# RL6678_IP_SVD register map
Vendor: Realtek
Registers are 32-bit, read-write, reset 0x0 unless marked. A register's access mark holds for its fields unless they carry their own. Offsets are from the block's base; [hi:lo] are bit positions; {n}, {i} and the like mark numbered series.

## PMC_REG
Base 0x42008300
0x00 REG_WAK_STATUS0 ro
  [31:0] wak_sta_31_0 — wak evt status. It can't be cleare here, clear at IP side . Bit0: WIFI_FISR_FESR_IRQ_LP Bit1: WIFI_FTSR_MAILBOX_IRQ_LP Bit2: AON Timer Bit3: NP_WAKE_IRQ_LP Bit4: AP_WAKE_IRQ_LP Bit5: WDG0_IRQ_LP Bit6: Timer0 Bit7: Timer1 Bit8: Timer2 Bit9: Timer3 Bit10: Timer4 Bit11: Timer5 Bit12: Timer6 Bit13: Timer7 Bit14: UART_LOG Bit15: GPIOA Bit16: GPIOB Bit17: GPIOC Bit18: RTC Bit19: CTOUCH Bit20: ADC Bit21: ADC_COMP Bit22: BOR Bit23: PWR_DOWN Bit24: VAD Bit25: IPC_NP Bit26: IPC_AP Bit27: USB_OTG Bit28: SPI0 Bit29: SPI1 Bit30: UART0 Bit31: UART1
0x04 REG_WAK_STATUS1 ro
  [31:0] wak_sta_63_32 — wak evt status. It can't be cleare here, clear at IP side . Bit0: UART2 Bit1: WDG1 Bit2: WDG2 Bit3: WDG3 Bit4: WDG4 Bit5: AON_GPIO_WAKE Bit6: BT_WAKE_HOST Bit7: nFIQOUT0_OR_nIRQOUT0 Bit8: nFIQOUT1_OR_nIRQOUT1 Bit9~31: Reserved
0x08 REG_WAK_MASK0_LP
  [31:0] wak_lp_imr_31_0 — 1:mask enable for wake KM0, this used to wak pmc
0x0C REG_WAK_MASK1_LP
  [31:0] wak_lp_imr_63_32 — 1:mask enable for wake KM0
0x10 REG_WAK_MASK0_NP
  [31:0] wak_np_imr_31_0 — 1:mask enable for wake NP
0x14 REG_WAK_MASK1_NP
  [31:0] wak_np_imr_63_32 — 1:mask enable for wake NP
0x18 REG_WAK_MASK0_AP
  [31:0] wak_ap_imr_31_0 — 1:mask enable for wake AP
0x1C REG_WAK_MASK1_AP
  [31:0] wak_ap_imr_63_32 — 1:mask enable for wake AP
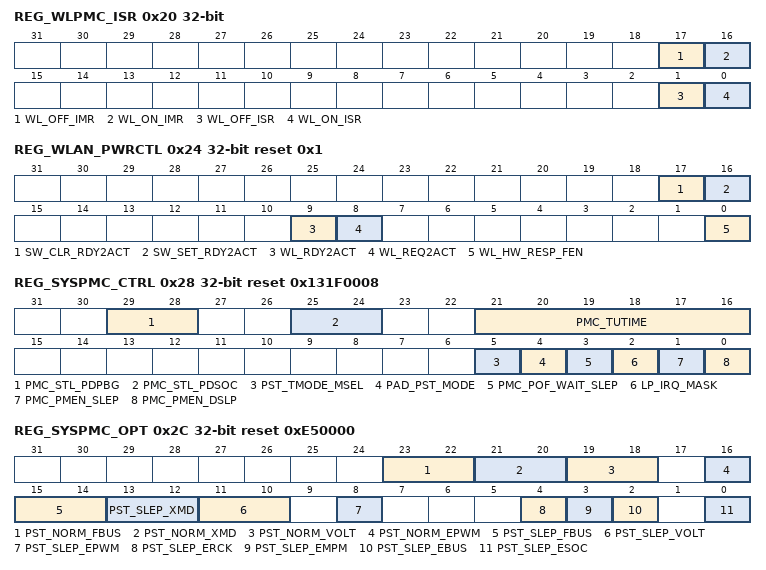
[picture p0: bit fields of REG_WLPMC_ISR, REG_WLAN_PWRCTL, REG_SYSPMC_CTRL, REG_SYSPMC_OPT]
0x20 REG_WLPMC_ISR access per field
  [17] WL_OFF_IMR rw, [16] WL_ON_IMR rw, [1] WL_OFF_ISR ro, [0] WL_ON_ISR ro
0x24 REG_WLAN_PWRCTL access per field reset 0x1
  [17] SW_CLR_RDY2ACT rw — System infrom WLAN ready to active
  [16] SW_SET_RDY2ACT rw
  [9] WL_RDY2ACT ro — System infrom WLAN ready to active
  [8] WL_REQ2ACT ro
  [0] WL_HW_RESP_FEN rw — 1: enable HW auto response
0x28 REG_SYSPMC_CTRL reset 0x131F0008
  [29:28] PMC_STL_PDPBG — timer wait for PLL bandgag power stable . Spec is 160us 00:8us * 2^4 01:8us * 2^5 10:8us * 2^6 11:8us * 2^7
  [25:24] PMC_STL_PDSOC — timer wait for core power power-cut power stable . 00:8us * 2^5 01:8us * 2^6 10:8us * 2^7 11:8us * 2^8
  [21:16] PMC_TUTIME — PMC timeunit setting, in cycles of osc4M e.g, default 0x1F, timeunit = 8us
  [5] PST_TMODE_MSEL — Set ls plfm msel option . 0: when test mode , msel will set to 0 for SIC 1: when test mode , pmc will not set msel , remain as km0 master.
  [4] PAD_PST_MODE — Pad pu/pd param selection 1: HW select pu/pd slp param for PAD 0: HW select pu/pd active param for PAD HW will auto-set this bit when enter or exit DSLP , SW can set for debug also .
  [3] PMC_POF_WAIT_SLEP — 1.when SW set pmen_slep or pmen_dslp , hw pmc will wait km0 enter sleep mode , then begin to pof seq 0.Not wait km0 sleep
  [2] LP_IRQ_MASK — 1.mask all LP interrupt 0:release all LP interrupt
  [1] PMC_PMEN_SLEP — 1: Request PMC to enter sleep state, auto clear to 0 after PMC finishes
  [0] PMC_PMEN_DSLP — 1: Request PMC to enter deep-sleep state, auto clear to 0 after PMC finishes
0x2C REG_SYSPMC_OPT reset 0xE50000
  [23:22] PST_NORM_FBUS — Normal setting for ls bus frequency selection 2'b00/01: ANA4M 2'b10: XTAL 2'b11: XTAL/2
  [21:20] PST_NORM_XMD — Normal setting for XTAL mode selection 00: XTAL will be off when PMC enter into sleep mode 01: XTAL will be in LPS when PMC enter into sleep mode 10/11: XTAL will be in Normal when PMC enter into sleep mode
  [19:18] PST_NORM_VOLT — Normal setting for SWR volt selection 00: SWR switch to LPS (0.8v) 01: SWR switch to NM (0.9v) 10/11: SWR switch to HP (1.0v)
  [16] PST_NORM_EPWM — Normal setting for SWR mode selection 1: SWR switch to PWM mode when nxt PMC enter into sleep mode 0: SWR switch to PFM when PMC enter into sleep mode
  [15:14] PST_SLEP_FBUS — Sleep setting for ls bus frequency selection 2'b00/01: ANA4M 2'b10: XTAL 2'b11: XTAL/2
  [13:12] PST_SLEP_XMD — Sleep setting for XTAL mode selection 00: XTAL will be off when PMC enter into sleep mode 01: XTAL will be in LPS when PMC enter into sleep mode 10/11: XTAL will be in Normal when PMC enter into sleep mode
  [11:10] PST_SLEP_VOLT — Sleep setting for SWR volt selection 00: SWR switch to LPS (0.8v) 01: SWR switch to NM (0.9v) 10/11: SWR switch to HP (1.0v)
  [8] PST_SLEP_EPWM — Sleep setting for SWR mode selection 1: SWR keeps at PWM mode when PMC enter into sleep mode 0: SWR switch to PFM when PMC enter into sleep mode
  [4] PST_SLEP_ERCK — 1: Enable osc4m platform clock when PMC enter into sleep mode 0: Gate osc4m platform clock when PMC enter into sleep mode
  [3] PST_SLEP_EMPM — 1: Enable LS system mem still in active when pmc enter sleep 0: LS system mem will in DSLP when pmc enter sleep
  [2] PST_SLEP_EBUS — 1: Enable platform clock when PMC entro into sleep mode 0: Gate platform clock when PMC entro into sleep mode
  [0] PST_SLEP_ESOC — 1: power enable SOC platform when PMC enter into sleep mode (clock-gating) 0: power off SoC domain when PMC enter into sleep mode (power-gating)
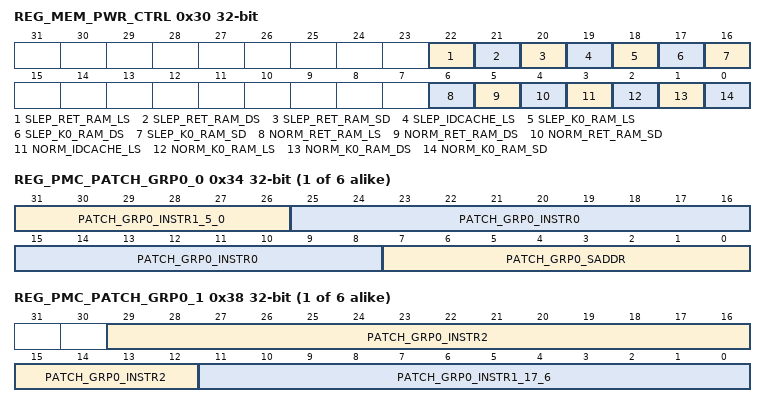
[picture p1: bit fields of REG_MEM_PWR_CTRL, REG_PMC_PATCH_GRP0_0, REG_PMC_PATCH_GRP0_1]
0x30 REG_MEM_PWR_CTRL
  [22] SLEP_RET_RAM_LS — 1: Enable Retention RAM light-sleep when KM0 in sleep state 0: Disable
  [21] SLEP_RET_RAM_DS — 1: Enable Retention RAM deep-sleep when KM0 in sleep state 0: Disable
  [20] SLEP_RET_RAM_SD — 1: Shut-down Retention RAM when KM0 in sleep state 0: Power on Retention RAM when KM0 in sleep state
  [19] SLEP_IDCACHE_LS — 1: Enable ICACHE/DCACHE light-sleep when KM0 in sleep state 0: Disable
  [18] SLEP_K0_RAM_LS — 1: Enable CPU RAM light-sleep when KM0 in sleep state 0: Disable
  [17] SLEP_K0_RAM_DS — 1: Enable CPU RAM deep-sleep when KM0 in sleep state 0: Disable
  [16] SLEP_K0_RAM_SD — 1: Shut-down CPU RAM when KM0 in sleep state 0: Power on CPU RAM when KM0 in sleep state
  [6] NORM_RET_RAM_LS — 1: Enable Retention RAM light-sleep when KM0 in active state 0: Disable
  [5] NORM_RET_RAM_DS — 1: Enable Retention RAM deep-sleep when KM0 in active state 0: Disable
  [4] NORM_RET_RAM_SD — 1: Shut-down Retention RAM when KM0 in active state 0: Power on Retention RAM when KM0 in active state
  [3] NORM_IDCACHE_LS — 1: Enable ICACHE/DCACHE light-sleep when KM0 in active state 0: Disable
  [2] NORM_K0_RAM_LS — 1: Enable CPU RAM light-sleep when KM0 in active state 0: Disable
  [1] NORM_K0_RAM_DS — 1: Enable CPU RAM deep-sleep when KM0 in active state 0: Disable
  [0] NORM_K0_RAM_SD — ECO_137 : KM0 itcm rom SLP
{0x34+8i} REG_PMC_PATCH_GRP{i}_0 (i=0..5)
  [31:26] PATCH_GRP{i}_INSTR1_5_0 — instruction1 of LSYSON PMC patch group{i},bit[5:0]
  [25:8] PATCH_GRP{i}_INSTR0 — instruction0 of LSYSON PMC patch group{i}
  [7:0] PATCH_GRP{i}_SADDR — Start address of the first instruction of LSYSON PMC patch group{i}
{0x38+8i} REG_PMC_PATCH_GRP{i}_1 (i=0..5)
  [29:12] PATCH_GRP{i}_INSTR2 — instruction2 of LSYSON PMC patch group{i}
  [11:0] PATCH_GRP{i}_INSTR1_17_6 — instruction1 of LSYSON PMC patch group{i},bit[17:6]
